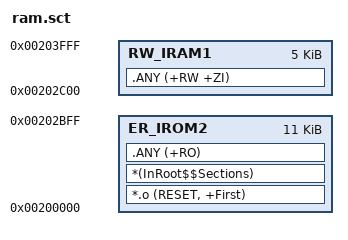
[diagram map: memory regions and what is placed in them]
; *************************************************************
; *** Scatter-Loading Description File generated by uVision ***
; *************************************************************

LR_IROM2 0x00200000 0x00002C00  {    ; load region size_region
  ER_IROM2 0x00200000 0x00002C00  {  ; load address = execution address
   *.o (RESET, +First)
   *(InRoot$$Sections)
   .ANY (+RO)
  }
  RW_IRAM1 0x00202C00 0x00001400  {  ; RW data
   .ANY (+RW +ZI)
  }
}

